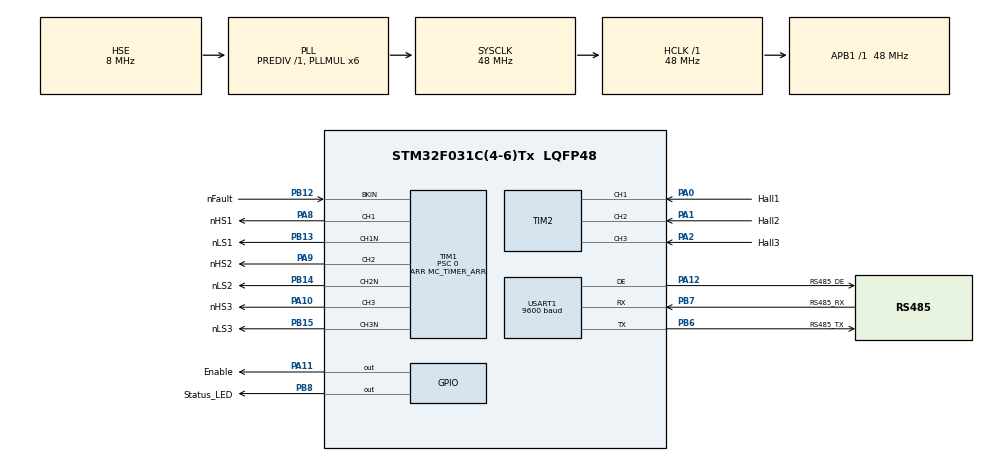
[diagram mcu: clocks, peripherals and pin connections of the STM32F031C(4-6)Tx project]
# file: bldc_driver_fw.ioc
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Dma.Request0=USART1_RX
Dma.USART1_RX.0.Direction=DMA_PERIPH_TO_MEMORY
Dma.USART1_RX.0.Instance=DMA1_Channel3
Dma.USART1_RX.0.MemDataAlignment=DMA_MDATAALIGN_BYTE
Dma.USART1_RX.0.MemInc=DMA_MINC_ENABLE
Dma.USART1_RX.0.Mode=DMA_CIRCULAR
Dma.USART1_RX.0.PeriphDataAlignment=DMA_PDATAALIGN_BYTE
Dma.USART1_RX.0.PeriphInc=DMA_PINC_DISABLE
Dma.USART1_RX.0.Priority=DMA_PRIORITY_LOW
Mcu.Family=STM32F0
Mcu.Name=STM32F031C(4-6)Tx
Mcu.Package=LQFP48
Mcu.UserConstants=MC_TIMER_ARR,2399
NVIC.DMA1_Channel2_3_IRQn=true\:1\:0\:true\:false\:true\:false\:true\:true
NVIC.TIM1_BRK_UP_TRG_COM_IRQn=true\:0\:0\:true\:false\:true\:true\:true\:true
NVIC.TIM2_IRQn=true\:0\:0\:false\:false\:true\:true\:true\:true
NVIC.USART1_IRQn=true\:2\:0\:true\:false\:true\:true\:true\:true
PA0.GPIO_Label=Hall1
PA0.Signal=S_TIM2_CH1_ETR
PA1.GPIO_Label=Hall2
PA1.Signal=S_TIM2_CH2
PA10.GPIO_Label=nHS3
PA10.GPIO_PuPd=GPIO_PULLUP
PA10.GPIO_Speed=GPIO_SPEED_FREQ_HIGH
PA10.Signal=S_TIM1_CH3
PA11.GPIO_Label=Enable
PA11.Signal=GPIO_Output
PA12.GPIO_Label=RS485_DE
PA12.Mode=Hardware Flow Control (RS485)
PA12.Signal=USART1_DE
PA13.GPIO_Label=SWDIO
PA13.Mode=Serial_Wire
PA13.Signal=SYS_SWDIO
PA14.GPIO_Label=SWCLK
PA14.Mode=Serial_Wire
PA14.Signal=SYS_SWCLK
PA2.GPIO_Label=Hall3
PA2.Signal=S_TIM2_CH3
PA8.GPIO_Label=nHS1
PA8.GPIO_PuPd=GPIO_PULLUP
PA8.GPIO_Speed=GPIO_SPEED_FREQ_HIGH
PA8.Signal=S_TIM1_CH1
PA9.GPIO_Label=nHS2
PA9.GPIO_PuPd=GPIO_PULLUP
PA9.GPIO_Speed=GPIO_SPEED_FREQ_HIGH
PA9.Signal=S_TIM1_CH2
PB12.GPIO_Label=nFault
PB12.Mode=Activate-Break-Input
PB12.Signal=TIM1_BKIN
PB13.GPIO_Label=nLS1
PB13.GPIO_PuPd=GPIO_PULLUP
PB13.GPIO_Speed=GPIO_SPEED_FREQ_HIGH
PB13.Mode=PWM Generation1 CH1 CH1N
PB13.Signal=TIM1_CH1N
PB14.GPIO_Label=nLS2
PB14.GPIO_PuPd=GPIO_PULLUP
PB14.GPIO_Speed=GPIO_SPEED_FREQ_HIGH
PB14.Mode=PWM Generation2 CH2 CH2N
PB14.Signal=TIM1_CH2N
PB15.GPIO_Label=nLS3
PB15.GPIO_PuPd=GPIO_PULLUP
PB15.GPIO_Speed=GPIO_SPEED_FREQ_HIGH
PB15.Mode=PWM Generation3 CH3 CH3N
PB15.Signal=TIM1_CH3N
PB6.GPIO_Label=RS485_TX
PB6.Mode=Asynchronous
PB6.Signal=USART1_TX
PB7.GPIO_Label=RS485_RX
PB7.Mode=Asynchronous
PB7.Signal=USART1_RX
PB8.GPIO_Label=Status_LED
PB8.Signal=GPIO_Output
PF0-OSC_IN.Mode=HSE-External-Oscillator
PF0-OSC_IN.Signal=RCC_OSC_IN
PF1-OSC_OUT.Mode=HSE-External-Oscillator
PF1-OSC_OUT.Signal=RCC_OSC_OUT
ProjectManager.HeapSize=0x200
ProjectManager.StackSize=0x400
ProjectManager.TargetToolchain=STM32CubeIDE
RCC.AHBFreq_Value=48000000
RCC.APB1Freq_Value=48000000
RCC.APB1TimFreq_Value=48000000
RCC.HCLKFreq_Value=48000000
RCC.PLLMUL=RCC_PLL_MUL6
RCC.PLLSourceVirtual=RCC_PLLSOURCE_HSE
RCC.SYSCLKFreq_VALUE=48000000
RCC.SYSCLKSource=RCC_SYSCLKSOURCE_PLLCLK
SH.S_TIM1_CH1.0=TIM1_CH1,PWM Generation1 CH1 CH1N
SH.S_TIM1_CH2.0=TIM1_CH2,PWM Generation2 CH2 CH2N
SH.S_TIM1_CH3.0=TIM1_CH3,PWM Generation3 CH3 CH3N
SH.S_TIM2_CH1_ETR.0=TIM2_CH1,Xored_Inputs_Hall_Sensor_Interface
SH.S_TIM2_CH2.0=TIM2_CH2,Xored_Inputs_Hall_Sensor_Interface
SH.S_TIM2_CH3.0=TIM2_CH3,Xored_Inputs_Hall_Sensor_Interface
TIM1.AutoReloadPreload=TIM_AUTORELOAD_PRELOAD_ENABLE
TIM1.BreakPolarity=TIM_BREAKPOLARITY_HIGH
TIM1.BreakState=TIM_BREAK_DISABLE
TIM1.Channel-PWM\ Generation1\ CH1\ CH1N=TIM_CHANNEL_1
TIM1.Channel-PWM\ Generation2\ CH2\ CH2N=TIM_CHANNEL_2
TIM1.Channel-PWM\ Generation3\ CH3\ CH3N=TIM_CHANNEL_3
TIM1.DeadTime=30
TIM1.OCNPolarity_1=TIM_OCNPOLARITY_LOW
TIM1.OCNPolarity_2=TIM_OCNPOLARITY_LOW
TIM1.OCNPolarity_3=TIM_OCNPOLARITY_LOW
TIM1.OCPolarity_1=TIM_OCPOLARITY_LOW
TIM1.OCPolarity_2=TIM_OCPOLARITY_LOW
TIM1.OCPolarity_3=TIM_OCPOLARITY_LOW
TIM1.Period=MC_TIMER_ARR
TIM1.Prescaler=0
TIM1.Pulse-PWM\ Generation1\ CH1\ CH1N=0
TIM1.Pulse-PWM\ Generation2\ CH2\ CH2N=0
TIM1.Pulse-PWM\ Generation3\ CH3\ CH3N=0
TIM1.TIM_MasterOutputTrigger=TIM_TRGO_RESET
TIM1.TIM_MasterSlaveMode=TIM_MASTERSLAVEMODE_DISABLE
TIM2.Commutation_Delay=2
TIM2.IC1Filter=8
USART1.BaudRate=9600
USART1.VirtualMode-Asynchronous=VM_ASYNC
USART1.VirtualMode-Hardware\ Flow\ Control\ (RS485)=VM_ASYNC
VP_TIM1_VS_ClockSourceITR.Mode=TriggerSource_ITR1
VP_TIM1_VS_ControllerModeReset.Mode=Reset Mode
board=custom

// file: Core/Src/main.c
/* USER CODE BEGIN Header */
/**
  ******************************************************************************
  * @file           : main.c
  * @brief          : Main program body
  ******************************************************************************
  * @attention
  *
  * Copyright (c) 2026 STMicroelectronics.
  * All rights reserved.
  *
  * This software is licensed under terms that can be found in the LICENSE file
  * in the root directory of this software component.
  * If no LICENSE file comes with this software, it is provided AS-IS.
  *
  ******************************************************************************
  */
/* USER CODE END Header */
#include "main.h"

/* USER CODE BEGIN Includes */
#include "mc_core.h"
#include "mc_cmd.h"
/* USER CODE END Includes */

TIM_HandleTypeDef htim1;
TIM_HandleTypeDef htim2;

UART_HandleTypeDef huart1;
DMA_HandleTypeDef hdma_usart1_rx;

void SystemClock_Config(void);
static void MX_GPIO_Init(void);
static void MX_DMA_Init(void);
static void MX_USART1_UART_Init(void);
static void MX_TIM1_Init(void);
static void MX_TIM2_Init(void);

int main(void)
{

  /* MCU Configuration--------------------------------------------------------*/

  /* Reset of all peripherals, Initializes the Flash interface and the Systick. */
  HAL_Init();

  /* Configure the system clock */
  SystemClock_Config();

  /* Initialize all configured peripherals */
  MX_GPIO_Init();
  MX_DMA_Init();
  MX_USART1_UART_Init();
  MX_TIM1_Init();
  MX_TIM2_Init();
  /* USER CODE BEGIN 2 */
  if (mc_core_init(&htim2, &htim1) != MC_FUNC_OK) {
	  Error_Handler();
  }
  if (mc_cmd_init(&huart1, &hdma_usart1_rx) != MC_FUNC_OK) {
	  Error_Handler();
  }
  /* USER CODE END 2 */

  /* Infinite loop */
  /* USER CODE BEGIN WHILE */
  while (1)
  {
	  /* Lowest priority tasks are run here */
	  mc_cmd_task();
	  mc_alarm_task();
    /* USER CODE END WHILE */

  }
}

void SystemClock_Config(void)
{
  RCC_OscInitTypeDef RCC_OscInitStruct = {0};
  RCC_ClkInitTypeDef RCC_ClkInitStruct = {0};
  RCC_PeriphCLKInitTypeDef PeriphClkInit = {0};

  /** Initializes the RCC Oscillators according to the specified parameters
  * in the RCC_OscInitTypeDef structure.
  */
  RCC_OscInitStruct.OscillatorType = RCC_OSCILLATORTYPE_HSE;
  RCC_OscInitStruct.HSEState = RCC_HSE_ON;
  RCC_OscInitStruct.PLL.PLLState = RCC_PLL_ON;
  RCC_OscInitStruct.PLL.PLLSource = RCC_PLLSOURCE_HSE;
  RCC_OscInitStruct.PLL.PLLMUL = RCC_PLL_MUL6;
  RCC_OscInitStruct.PLL.PREDIV = RCC_PREDIV_DIV1;
  if (HAL_RCC_OscConfig(&RCC_OscInitStruct) != HAL_OK)
  {
    Error_Handler();
  }

  /** Initializes the CPU, AHB and APB buses clocks
  */
  RCC_ClkInitStruct.ClockType = RCC_CLOCKTYPE_HCLK|RCC_CLOCKTYPE_SYSCLK
                              |RCC_CLOCKTYPE_PCLK1;
  RCC_ClkInitStruct.SYSCLKSource = RCC_SYSCLKSOURCE_PLLCLK;
  RCC_ClkInitStruct.AHBCLKDivider = RCC_SYSCLK_DIV1;
  RCC_ClkInitStruct.APB1CLKDivider = RCC_HCLK_DIV1;

  if (HAL_RCC_ClockConfig(&RCC_ClkInitStruct, FLASH_LATENCY_1) != HAL_OK)
  {
    Error_Handler();
  }
  PeriphClkInit.PeriphClockSelection = RCC_PERIPHCLK_USART1;
  PeriphClkInit.Usart1ClockSelection = RCC_USART1CLKSOURCE_PCLK1;
  if (HAL_RCCEx_PeriphCLKConfig(&PeriphClkInit) != HAL_OK)
  {
    Error_Handler();
  }
}

static void MX_TIM1_Init(void)
{

  TIM_SlaveConfigTypeDef sSlaveConfig = {0};
  TIM_MasterConfigTypeDef sMasterConfig = {0};
  TIM_OC_InitTypeDef sConfigOC = {0};
  TIM_BreakDeadTimeConfigTypeDef sBreakDeadTimeConfig = {0};

  htim1.Instance = TIM1;
  htim1.Init.Prescaler = 0;
  htim1.Init.CounterMode = TIM_COUNTERMODE_UP;
  htim1.Init.Period = MC_TIMER_ARR;
  htim1.Init.ClockDivision = TIM_CLOCKDIVISION_DIV1;
  htim1.Init.RepetitionCounter = 0;
  htim1.Init.AutoReloadPreload = TIM_AUTORELOAD_PRELOAD_ENABLE;
  if (HAL_TIM_Base_Init(&htim1) != HAL_OK)
  {
    Error_Handler();
  }
  if (HAL_TIM_PWM_Init(&htim1) != HAL_OK)
  {
    Error_Handler();
  }
  sSlaveConfig.SlaveMode = TIM_SLAVEMODE_RESET;
  sSlaveConfig.InputTrigger = TIM_TS_ITR1;
  if (HAL_TIM_SlaveConfigSynchro(&htim1, &sSlaveConfig) != HAL_OK)
  {
    Error_Handler();
  }
  sMasterConfig.MasterOutputTrigger = TIM_TRGO_RESET;
  sMasterConfig.MasterSlaveMode = TIM_MASTERSLAVEMODE_DISABLE;
  if (HAL_TIMEx_MasterConfigSynchronization(&htim1, &sMasterConfig) != HAL_OK)
  {
    Error_Handler();
  }
  sConfigOC.OCMode = TIM_OCMODE_PWM1;
  sConfigOC.Pulse = 0;
  sConfigOC.OCPolarity = TIM_OCPOLARITY_LOW;
  sConfigOC.OCNPolarity = TIM_OCNPOLARITY_LOW;
  sConfigOC.OCFastMode = TIM_OCFAST_DISABLE;
  sConfigOC.OCIdleState = TIM_OCIDLESTATE_RESET;
  sConfigOC.OCNIdleState = TIM_OCNIDLESTATE_RESET;
  if (HAL_TIM_PWM_ConfigChannel(&htim1, &sConfigOC, TIM_CHANNEL_1) != HAL_OK)
  {
    Error_Handler();
  }
  if (HAL_TIM_PWM_ConfigChannel(&htim1, &sConfigOC, TIM_CHANNEL_2) != HAL_OK)
  {
    Error_Handler();
  }
  if (HAL_TIM_PWM_ConfigChannel(&htim1, &sConfigOC, TIM_CHANNEL_3) != HAL_OK)
  {
    Error_Handler();
  }
  sBreakDeadTimeConfig.OffStateRunMode = TIM_OSSR_DISABLE;
  sBreakDeadTimeConfig.OffStateIDLEMode = TIM_OSSI_DISABLE;
  sBreakDeadTimeConfig.LockLevel = TIM_LOCKLEVEL_OFF;
  sBreakDeadTimeConfig.DeadTime = 30;
  sBreakDeadTimeConfig.BreakState = TIM_BREAK_DISABLE;
  sBreakDeadTimeConfig.BreakPolarity = TIM_BREAKPOLARITY_HIGH;
  sBreakDeadTimeConfig.AutomaticOutput = TIM_AUTOMATICOUTPUT_DISABLE;
  if (HAL_TIMEx_ConfigBreakDeadTime(&htim1, &sBreakDeadTimeConfig) != HAL_OK)
  {
    Error_Handler();
  }
  HAL_TIM_MspPostInit(&htim1);

}

static void MX_TIM2_Init(void)
{

  TIM_HallSensor_InitTypeDef sConfig = {0};
  TIM_MasterConfigTypeDef sMasterConfig = {0};

  htim2.Instance = TIM2;
  htim2.Init.Prescaler = 0;
  htim2.Init.CounterMode = TIM_COUNTERMODE_UP;
  htim2.Init.Period = 4294967295;
  htim2.Init.ClockDivision = TIM_CLOCKDIVISION_DIV1;
  htim2.Init.AutoReloadPreload = TIM_AUTORELOAD_PRELOAD_DISABLE;
  sConfig.IC1Polarity = TIM_ICPOLARITY_RISING;
  sConfig.IC1Prescaler = TIM_ICPSC_DIV1;
  sConfig.IC1Filter = 8;
  sConfig.Commutation_Delay = 2;
  if (HAL_TIMEx_HallSensor_Init(&htim2, &sConfig) != HAL_OK)
  {
    Error_Handler();
  }
  sMasterConfig.MasterOutputTrigger = TIM_TRGO_OC2REF;
  sMasterConfig.MasterSlaveMode = TIM_MASTERSLAVEMODE_DISABLE;
  if (HAL_TIMEx_MasterConfigSynchronization(&htim2, &sMasterConfig) != HAL_OK)
  {
    Error_Handler();
  }

}

static void MX_USART1_UART_Init(void)
{

  huart1.Instance = USART1;
  huart1.Init.BaudRate = 9600;
  huart1.Init.WordLength = UART_WORDLENGTH_8B;
  huart1.Init.StopBits = UART_STOPBITS_1;
  huart1.Init.Parity = UART_PARITY_NONE;
  huart1.Init.Mode = UART_MODE_TX_RX;
  huart1.Init.HwFlowCtl = UART_HWCONTROL_NONE;
  huart1.Init.OverSampling = UART_OVERSAMPLING_16;
  huart1.Init.OneBitSampling = UART_ONE_BIT_SAMPLE_DISABLE;
  huart1.AdvancedInit.AdvFeatureInit = UART_ADVFEATURE_NO_INIT;
  if (HAL_RS485Ex_Init(&huart1, UART_DE_POLARITY_HIGH, 0, 0) != HAL_OK)
  {
    Error_Handler();
  }

}

static void MX_DMA_Init(void)
{

  /* DMA controller clock enable */
  __HAL_RCC_DMA1_CLK_ENABLE();

  /* DMA interrupt init */
  /* DMA1_Channel2_3_IRQn interrupt configuration */
  HAL_NVIC_SetPriority(DMA1_Channel2_3_IRQn, 1, 0);
  HAL_NVIC_EnableIRQ(DMA1_Channel2_3_IRQn);

}

static void MX_GPIO_Init(void)
{
  GPIO_InitTypeDef GPIO_InitStruct = {0};

  /* GPIO Ports Clock Enable */
  __HAL_RCC_GPIOF_CLK_ENABLE();
  __HAL_RCC_GPIOA_CLK_ENABLE();
  __HAL_RCC_GPIOB_CLK_ENABLE();

  /*Configure GPIO pin Output Level */
  HAL_GPIO_WritePin(Enable_GPIO_Port, Enable_Pin, GPIO_PIN_RESET);

  /*Configure GPIO pin Output Level */
  HAL_GPIO_WritePin(Status_LED_GPIO_Port, Status_LED_Pin, GPIO_PIN_RESET);

  /*Configure GPIO pin : Enable_Pin */
  GPIO_InitStruct.Pin = Enable_Pin;
  GPIO_InitStruct.Mode = GPIO_MODE_OUTPUT_PP;
  GPIO_InitStruct.Pull = GPIO_NOPULL;
  GPIO_InitStruct.Speed = GPIO_SPEED_FREQ_LOW;
  HAL_GPIO_Init(Enable_GPIO_Port, &GPIO_InitStruct);

  /*Configure GPIO pin : Status_LED_Pin */
  GPIO_InitStruct.Pin = Status_LED_Pin;
  GPIO_InitStruct.Mode = GPIO_MODE_OUTPUT_PP;
  GPIO_InitStruct.Pull = GPIO_NOPULL;
  GPIO_InitStruct.Speed = GPIO_SPEED_FREQ_LOW;
  HAL_GPIO_Init(Status_LED_GPIO_Port, &GPIO_InitStruct);

}

void Error_Handler(void)
{
  /* USER CODE BEGIN Error_Handler_Debug */
	/* User can add his own implementation to report the HAL error return state */
	__disable_irq();

	// Signal error state
	volatile uint32_t i;
	while (1)
	{
		HAL_GPIO_TogglePin(Status_LED_GPIO_Port, Status_LED_Pin);
		for (i = 0; i < 2500000UL; i++) {} //Busy wait loop for ~0.2083 s
	}
  /* USER CODE END Error_Handler_Debug */
}
